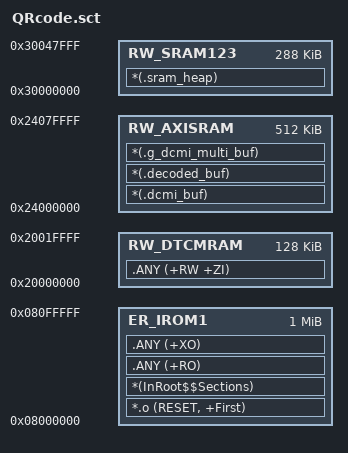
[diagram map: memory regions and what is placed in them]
; *************************************************************
; *** Scatter-Loading Description File generated by uVision ***
; *************************************************************

LR_IROM1 0x08000000 0x00100000  {    ; load region size_region
  ER_IROM1 0x08000000 0x00100000  {  ; load address = execution address
   *.o (RESET, +First)
   *(InRoot$$Sections)
   .ANY (+RO)
   .ANY (+XO)
  }
  RW_DTCMRAM 0x20000000 0x00020000  {  ; RW data  128KB 400MHZ DATA
    .ANY (+RW +ZI)
  }
  RW_AXISRAM 0x24000000 0x00080000  {  ; RW data  512KB 200MHZ DATA
    *(.dcmi_buf)
    *(.decoded_buf)
    *(.g_dcmi_multi_buf)
  }
  RW_SRAM123 0x30000000 0x48000 {    ; RW data  288KB 200MHZ DATA
    *(.sram_heap)
  }
}

